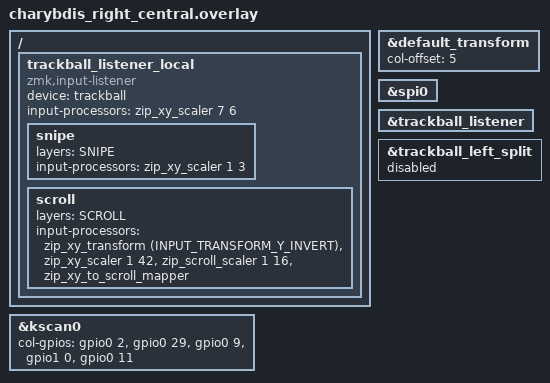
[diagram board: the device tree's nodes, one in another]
#include "charybdis.dtsi"
#include "charybdis_3610.dtsi"
#include "split_input.dtsi"

/ {
	trackball_listener_local: trackball_listener_local {
		compatible = "zmk,input-listener";
		device = <&trackball>;

		input-processors = <&zip_xy_scaler 7 6>;

		snipe {
			layers = <SNIPE>;
			input-processors = <&zip_xy_scaler 1 3>;
		};

		scroll {
			layers = <SCROLL>;
			input-processors = <
				&zip_xy_transform (INPUT_TRANSFORM_Y_INVERT)
				&zip_xy_scaler 1 42
				&zip_scroll_scaler 1 16
				&zip_xy_to_scroll_mapper
			>;
		};
	};
};

&default_transform {
	col-offset = <5>;
};

&kscan0 {
	col-gpios
		= <&gpio0 2 (GPIO_ACTIVE_HIGH | GPIO_PULL_DOWN)>
		, <&gpio0 29 (GPIO_ACTIVE_HIGH | GPIO_PULL_DOWN)>
		, <&gpio0 9 (GPIO_ACTIVE_HIGH | GPIO_PULL_DOWN)>
		, <&gpio1 0  (GPIO_ACTIVE_HIGH | GPIO_PULL_DOWN)>
		, <&gpio0 11 (GPIO_ACTIVE_HIGH | GPIO_PULL_DOWN)>
		
		;
};

&spi0 {
    status = "okay";
};

&trackball_listener {
    status = "okay";
};

&trackball_left_split {
    status = "disabled";
};
